AUTOSAR XML (schema 4-2-2)
package /ComponentTypes
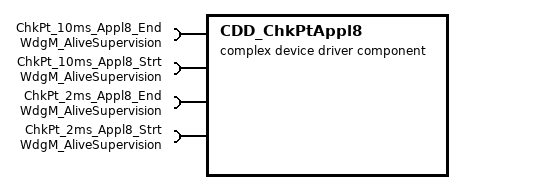
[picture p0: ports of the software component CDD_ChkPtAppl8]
  complex device driver sw component type CDD_ChkPtAppl8
    4 x require port, all with client-com-spec=CheckpointReached, required-interface=WdgM_AliveSupervision:
      ChkPt_10ms_Appl8_End
      ChkPt_10ms_Appl8_Strt
      ChkPt_2ms_Appl8_End
      ChkPt_2ms_Appl8_Strt
    behavior CDD_ChkPtAppl8_InternalBehavior
      4 x timing event:
        TMT_ChkPt_10msAppl8End: start-on-event=ChkPt_10msAppl8End, period=0.01
        TMT_ChkPt_10msAppl8Strt: start-on-event=ChkPt_10msAppl8Strt, period=0.01
        TMT_ChkPt_2msAppl8End: start-on-event=ChkPt_2msAppl8End, period=0.002
        TMT_ChkPt_2msAppl8Strt: start-on-event=ChkPt_2msAppl8Strt, period=0.002
      port-api-options:
        enable-take-address=false, error-handling=NO-TRANSFORMER-ERROR-HANDLING, indirect-api=false, port=ChkPt_10ms_Appl8_End
        enable-take-address=false, error-handling=NO-TRANSFORMER-ERROR-HANDLING, indirect-api=false, port=ChkPt_10ms_Appl8_Strt
        enable-take-address=false, error-handling=NO-TRANSFORMER-ERROR-HANDLING, indirect-api=false, port=ChkPt_2ms_Appl8_End
        enable-take-address=false, error-handling=NO-TRANSFORMER-ERROR-HANDLING, indirect-api=false, port=ChkPt_2ms_Appl8_Strt
      4 x runnable:
        ChkPt_10msAppl8End
          sync call SC_ChkPt_10ms_Appl8_End_CheckpointReached: operation=ChkPt_10ms_Appl8_End.CheckpointReached, timeout=0
        ChkPt_10msAppl8Strt
          sync call SC_ChkPt_10ms_Appl8_Strt_CheckpointReached: operation=ChkPt_10ms_Appl8_Strt.CheckpointReached, timeout=0
        ChkPt_2msAppl8End
          sync call SC_ChkPt_2ms_Appl8_End_CheckpointReached: operation=ChkPt_2ms_Appl8_End.CheckpointReached, timeout=0
        ChkPt_2msAppl8Strt
          sync call SC_ChkPt_2ms_Appl8_Strt_CheckpointReached: operation=ChkPt_2ms_Appl8_Strt.CheckpointReached, timeout=0
  swc implementation CDD_ChkPtAppl8_Implementation: behavior=CDD_ChkPtAppl8_InternalBehavior
    code-descriptors:
      code Default: artifact-descriptors=autosar-engineering-object={short-label=Default, category=SWSRC}
